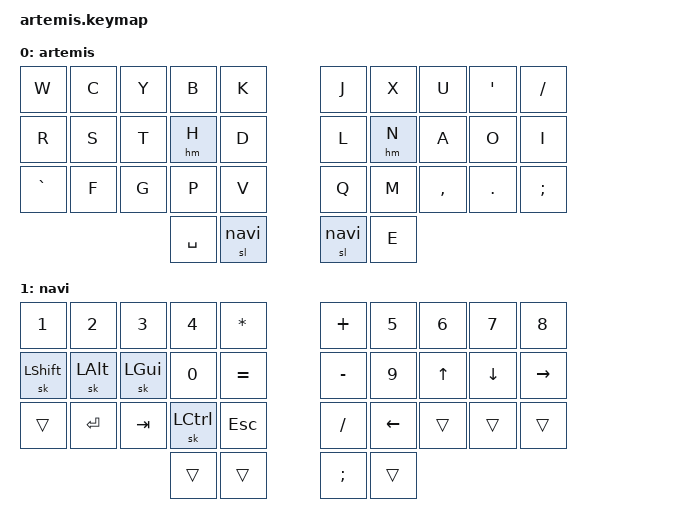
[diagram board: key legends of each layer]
/*
 * Copyright (c) 2020 The ZMK Contributors
 *
 * SPDX-License-Identifier: MIT
 */

#include <behaviors.dtsi>
#include <dt-bindings/zmk/keys.h>
#include <dt-bindings/zmk/bt.h>

#define artemis 0
#define navi    1

/ {
    combos {
        #include "combos.dtsi"
    };
    
    behaviors {
        skq: sticky_key_quick_release {
            compatible = "zmk,behavior-sticky-key";
            label = "STICKY_KEY_QUICK_RELEASE";
            #binding-cells = <1>;
            bindings = <&kp>;
            quick-release;
            release-after-ms = <1000>;
        };
        hm: homerow_mods {
            compatible = "zmk,behavior-hold-tap";
            label = "HOMEROW_MODS";
            #binding-cells = <2>;
            tapping-term-ms = <169>;
            quick_tap_ms = <169>;
            flavor = "tap-preferred";
            bindings = <&kp>, <&kp>;
        };
    };

    keymap {
        compatible = "zmk,keymap";
                
        artemis_layer {
            label = "artemis";
            bindings = <
                &kp W     &kp C &kp Y &kp B &kp K        &kp J &kp X &kp U     &kp SQT &kp FSLH
                &kp R     &kp S &kp T &hm H &kp D        &kp L &hm N &kp A     &kp O   &kp I
                &kp GRAVE &kp F &kp G &kp P &kp V        &kp Q &kp M &kp COMMA &kp DOT &kp SEMI
                            &kp SPACE &sl navi            &sl navi &kp E
            >;
        };
                
        navi_layer {
            label = "navi";
            bindings = <
                &kp N1    &kp N2   &kp N3   &kp N4   &kp STAR        &kp PLUS  &kp N5   &kp N6 &kp N7   &kp N8
                &sk LSHFT &sk LALT &sk LGUI &kp N0   &kp EQUAL       &kp MINUS &kp N9   &kp UP &kp DOWN &kp RIGHT
                &trans    &kp RET  &kp TAB  &sk LCTL &kp ESC         &kp FSLH  &kp LEFT &trans &trans   &trans
                            &trans &trans                              &kp SEMI &trans 
            >;
        };
    };
};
